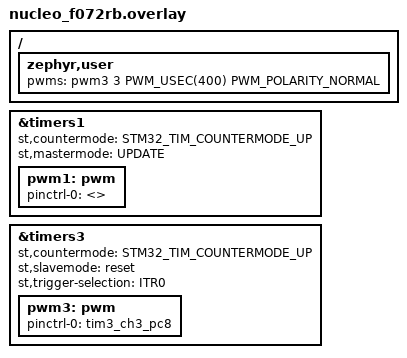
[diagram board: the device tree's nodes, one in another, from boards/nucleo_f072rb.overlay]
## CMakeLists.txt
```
# SPDX-License-Identifier: Apache-2.0

cmake_minimum_required(VERSION 3.28.0)
find_package(Zephyr REQUIRED HINTS $ENV{ZEPHYR_BASE})
project(mastermode)

FILE(GLOB app_sources src/*.c)
target_sources(app PRIVATE ${app_sources})
```

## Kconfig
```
# Copyright (c) 2025 Matthias Plöger <matze.ploeger@gmx.de>
# SPDX-License-Identifier: Apache-2.0

menu "Zephyr"
source "Kconfig.zephyr"
endmenu

module = MAIN
module-str = MAIN
source "subsys/logging/Kconfig.template.log_config"
```

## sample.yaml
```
sample:
  name: STM32 pwm mastermode
tests:
  sample.boards.stm32.pwm.mastermode:
    depends_on: pwm
    tags:
      - drivers
      - pwm
    filter: dt_compat_enabled("st,stm32-timers")
    platform_allow:
      - nucleo_g070rb
      - nucleo_g071rb
    harness: console
    harness_config:
      type: one_line
      regex:
        - "TRGO event will be generated every.*"
```

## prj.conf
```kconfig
# SPDX-FileCopyrightText: Copyright The Zephyr Project Contributors
# SPDX-License-Identifier: Apache-2.0

CONFIG_LOG=y
CONFIG_PWM=y
```

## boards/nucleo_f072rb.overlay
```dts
/*
 * Copyright (c) 2026 Matthias Plöger <matze.ploeger@gmx.de>
 *
 * SPDX-License-Identifier: Apache-2.0
 */

#include <dt-bindings/timer/stm32-timer.h>

/ {
	zephyr,user {
		pwms = <&pwm3 3 PWM_USEC(400) PWM_POLARITY_NORMAL>;
	};
};

&timers1 {
	/**
	 * Configure the TRGO output and counter mode of the timer instance.
	 * A TRGO event is generated at each timer update event
	 * (i.e., after each time the timer counter overflows)
	 */
	st,countermode = <STM32_TIM_COUNTERMODE_UP>;
	st,mastermode = "UPDATE";
	status = "okay";

	pwm1: pwm {
		pinctrl-0 = <>;
		pinctrl-names = "default";
		status = "okay";
	};
};

&timers3 {
	/**
	 * Configure TIM3 to be reset every time TIM1 overflows.
	 * Select TIM1 TRGO signal as input (= ITR0). Refer to RM0454 Rev.5
	 * table 66 "TIM2 and TIM3 internal trigger connection" for details.
	 */
	st,countermode = <STM32_TIM_COUNTERMODE_UP>;
	st,slavemode = "reset";
	st,trigger-selection = "ITR0";
	status = "okay";

	pwm3: pwm {
		pinctrl-0 = <&tim3_ch3_pc8>;
		pinctrl-names = "default";
		status = "okay";
	};
};
```

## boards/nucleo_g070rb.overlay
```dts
/*
 * Copyright (c) 2025 Matthias Plöger <matze.ploeger@gmx.de>
 *
 * SPDX-License-Identifier: Apache-2.0
 */

#include <dt-bindings/timer/stm32-timer.h>

/ {
	zephyr,user {
		pwms = <&pwm3 1 PWM_USEC(400) PWM_POLARITY_NORMAL>;
	};
};

&timers1 {
	/**
	 * Configure the TRGO output and counter mode of the timer instance.
	 * A TRGO event is generated at each timer update event
	 * (i.e., after each time the timer counter overflows)
	 */
	st,countermode = <STM32_TIM_COUNTERMODE_UP>;
	st,mastermode = "UPDATE";
	status = "okay";

	pwm1: pwm {
		pinctrl-0 = <>;
		pinctrl-names = "default";
		status = "okay";
	};
};

&timers3 {
	/**
	 * Configure TIM3 to be reset every time TIM1 overflows.
	 * Select TIM1 TRGO signal as input (= ITR0). Refer to RM0091 Rev.10
	 * table 73 "TIM3 internal trigger connection" for details.
	 */
	st,countermode = <STM32_TIM_COUNTERMODE_UP>;
	st,slavemode = "reset";
	st,trigger-selection = "ITR0";
};
```

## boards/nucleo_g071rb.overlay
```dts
/*
 * Copyright (c) 2025 Matthias Plöger <matze.ploeger@gmx.de>
 *
 * SPDX-License-Identifier: Apache-2.0
 */

#include <dt-bindings/timer/stm32-timer.h>

/ {
	zephyr,user {
		pwms = <&pwm3 1 PWM_USEC(400) PWM_POLARITY_NORMAL>;
	};
};

&timers1 {
	/**
	 * Configure the TRGO output and counter mode of the timer instance.
	 * A TRGO event is generated at each timer update event
	 * (i.e., after each time the timer counter overflows)
	 */
	st,countermode = <STM32_TIM_COUNTERMODE_UP>;
	st,mastermode = "UPDATE";
	status = "okay";

	pwm1: pwm {
		pinctrl-0 = <>;
		pinctrl-names = "default";
		status = "okay";
	};
};

&timers3 {
	/**
	 * Configure TIM3 to be reset every time TIM1 overflows.
	 * Select TIM1 TRGO signal as input (= ITR0). Refer to RM0444 Rev.6
	 * table 123 "TIMx internal trigger connection" for details.
	 */
	st,countermode = <STM32_TIM_COUNTERMODE_UP>;
	st,slavemode = "reset";
	st,trigger-selection = "ITR0";
};
```

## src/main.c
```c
/*
 * Copyright (c) 2025 Matthias Plöger <matze.ploeger@gmx.de>
 *
 * SPDX-License-Identifier: Apache-2.0
 */

#include <zephyr/drivers/pwm.h>
#include <zephyr/kernel.h>

#include <zephyr/logging/log.h>
LOG_MODULE_REGISTER(main, CONFIG_MAIN_LOG_LEVEL);

#define PWM_PERIOD1_US    400 /* PWM period duration */
#define PWM_PERIOD2_US    300 /* PWM period duration */
#define PWM_PERIOD3_US    200 /* PWM period duration */
#define PWM_PULSE_TIME_US 100 /* PWM on/pulse/high time*/

static const struct device *pwm_master = DEVICE_DT_GET(DT_NODELABEL(pwm1));
static struct pwm_dt_spec pwm_slave = PWM_DT_SPEC_GET(DT_PATH(zephyr_user));

int main(void)
{
	int ret;

	if (!device_is_ready(pwm_master)) {
		LOG_ERR("%s: pwm device not ready", pwm_master->name);
		return 0;
	}
	if (!device_is_ready(pwm_slave.dev)) {
		LOG_ERR("%s: pwm device not ready", pwm_slave.dev->name);
		return 0;
	}

	LOG_INF("slave PWM T=%dus, Ton=%dus", PWM_PERIOD1_US, PWM_PULSE_TIME_US);
	ret = pwm_set_dt(&pwm_slave, PWM_USEC(PWM_PERIOD1_US), PWM_USEC(PWM_PULSE_TIME_US));
	if (ret < 0) {
		LOG_ERR("pwm_set_dt() failed: %d", ret);
		return 0;
	}

	while (true) {
		k_sleep(K_MSEC(2000));

		LOG_INF("Set period of master PWM to %dus", PWM_PERIOD2_US);
		ret = pwm_set(pwm_master, 1, PWM_USEC(PWM_PERIOD2_US), 0, PWM_POLARITY_NORMAL);
		if (ret < 0) {
			LOG_ERR("pwm_set() failed: %d", ret);
			return 0;
		}
		LOG_INF("--> slave PWM T=%dus, Ton=%dus\n", PWM_PERIOD2_US, PWM_PULSE_TIME_US);

		k_sleep(K_MSEC(2000));

		LOG_INF("Set period of master PWM to %dus", PWM_PERIOD3_US);
		ret = pwm_set(pwm_master, 1, PWM_USEC(PWM_PERIOD3_US), 0, PWM_POLARITY_NORMAL);
		if (ret < 0) {
			LOG_ERR("pwm_set() failed: %d", ret);
			return 0;
		}
		LOG_INF("--> slave PWM T=%dus, Ton=%dus\n", PWM_PERIOD3_US, PWM_PULSE_TIME_US);
	}

	return 0;
}
```
